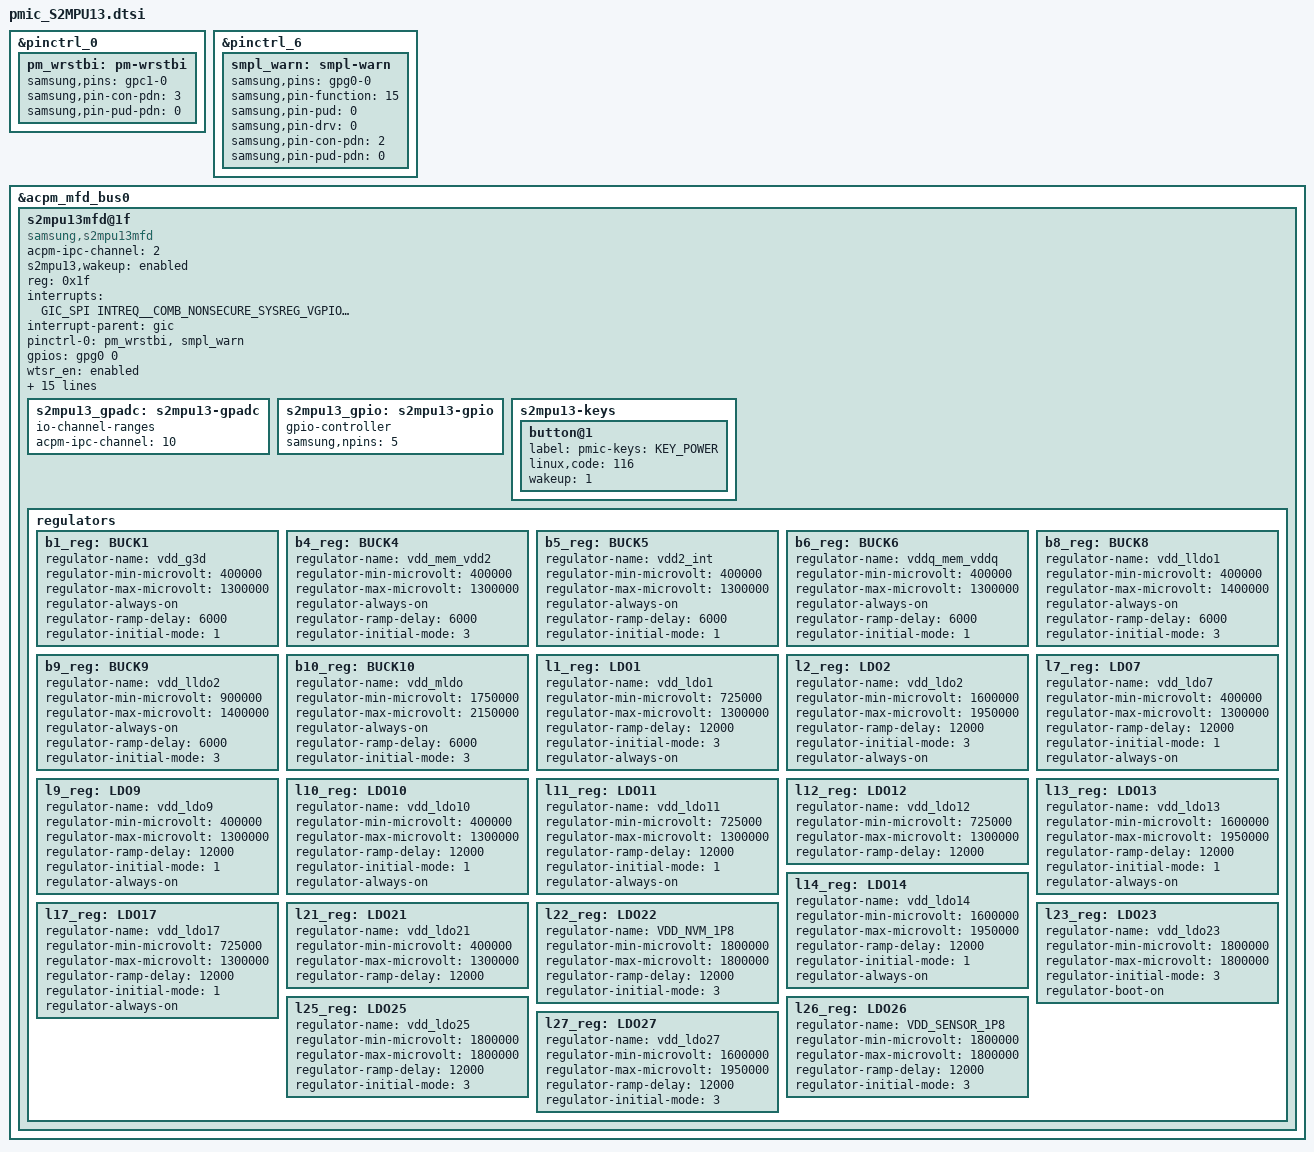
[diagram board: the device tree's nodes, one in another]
#include <dt-bindings/interrupt-controller/s5e8825.h>

&pinctrl_0 {
	pm_wrstbi: pm-wrstbi {
		   samsung,pins = "gpc1-0";
		   samsung,pin-con-pdn = <3>;
		   samsung,pin-pud-pdn = <0>;
	};
};

&pinctrl_6 {
	smpl_warn: smpl-warn {
		   samsung,pins = "gpg0-0";
		   samsung,pin-function = <15>;
		   samsung,pin-pud = <0>;
		   samsung,pin-drv = <0>;
		   samsung,pin-con-pdn = <2>;
		   samsung,pin-pud-pdn = <0>;
	};
};

&acpm_mfd_bus0 {
	status = "okay";
	#address-cells = <1>;
	#size-cells = <0>;

	s2mpu13mfd@1f {
		compatible = "samsung,s2mpu13mfd";
		acpm-ipc-channel = <2>;
		s2mpu13,wakeup = "enabled";
		reg = <0x1f>;
		interrupts = <GIC_SPI INTREQ__COMB_NONSECURE_SYSREG_VGPIO2AP IRQ_TYPE_LEVEL_HIGH>;
		interrupt-parent = <&gic>;
		pinctrl-names = "default";
		pinctrl-0 = <&pm_wrstbi &smpl_warn>;
		gpios = <&gpg0 0 0>;
		/* RTC: wtsr/smpl */
		wtsr_en = "enabled"; /* enable */
		smpl_en = "enabled"; /* enable */
		wtsr_timer_val = <3>;	/* 1000ms */
		smpl_timer_val = <0>;	/* 100ms */
		sub_smpl_en = "enabled"; /* enable */
		check_jigon = <0>; /* do not check jigon */
		/* RTC: If it's first boot, reset rtc to 1/1/2021 12:00:00(Wed) */
		init_time,sec = <0>;
		init_time,min = <0>;
		init_time,hour = <12>;
		init_time,mday = <1>;
		init_time,mon = <0>;
		init_time,year = <121>;
		init_time,wday = <5>;
		/* SMPL_WARN */
		smpl_warn_en = <1>; /* 1 : enable , 0 : disable */

		/* SEL_VGPIO0M~18M (CONTROL_SEL#) */
		sel_vgpio = <0x24 0x32 0x11 0x39 0x33 0x33 0x22 0x33 0x24 0xB1
			     0xC1 0xB1 0x77 0x5B 0x5E 0xCC 0x73 0x33 0xF3>;

		s2mpu13_gpadc: s2mpu13-gpadc {
			#io-channel-cells = <1>;
			io-channel-ranges;
			acpm-ipc-channel = <10>;
		};

		s2mpu13_gpio: s2mpu13-gpio {
			gpio-controller;
			#gpio-cells = <2>;
			samsung,npins = <5>;
			status = "okay";
		};

		s2mpu13-keys {
			button@1 {
				label = "pmic-keys: KEY_POWER";
				linux,code = <116>;
				wakeup = <1>;
			};
		};

		regulators {
			b1_reg: BUCK1 {
				regulator-name = "vdd_g3d";
				regulator-min-microvolt = <400000>;
				regulator-max-microvolt = <1300000>;
				regulator-always-on;
				regulator-ramp-delay = <6000>;
				regulator-initial-mode = <1>;                   /* V_PWREN_G3D */
			};
/*
			b2_reg: BUCK2 {
				regulator-name = "vdd_cpu_cp";
				regulator-min-microvolt = <400000>;
				regulator-max-microvolt = <1300000>;
				regulator-always-on;
				regulator-ramp-delay = <6000>;
				regulator-initial-mode = <3>;
			};

			b3_reg: BUCK3 {
				regulator-name = "vdd_cp";
				regulator-min-microvolt = <400000>;
				regulator-max-microvolt = <1300000>;
				regulator-always-on;
				regulator-ramp-delay = <6000>;
				regulator-initial-mode = <3>;
			};
*/
			b4_reg: BUCK4 {
				regulator-name = "vdd_mem_vdd2";
				regulator-min-microvolt = <400000>;
				regulator-max-microvolt = <1300000>;
				regulator-always-on;
				regulator-ramp-delay = <6000>;
				regulator-initial-mode = <3>;                   /* V_PWREN_MIF */
			};

			b5_reg: BUCK5 {
				regulator-name = "vdd2_int";
				regulator-min-microvolt = <400000>;
				regulator-max-microvolt = <1300000>;
				regulator-always-on;
				regulator-ramp-delay = <6000>;
				regulator-initial-mode = <1>;                   /* V_PWREN_MIF */
			};

			b6_reg: BUCK6 {
				regulator-name = "vddq_mem_vddq";
				regulator-min-microvolt = <400000>;
				regulator-max-microvolt = <1300000>;
				regulator-always-on;
				regulator-ramp-delay = <6000>;
				regulator-initial-mode = <1>;                   /* V_PWREN_MIF */
			};
/*
			b7_reg: BUCK7 {
				regulator-name = "vdd_wlbt";
				regulator-min-microvolt = <400000>;
				regulator-max-microvolt = <1300000>;
				regulator-always-on;
				regulator-ramp-delay = <6000>;
				regulator-initial-mode = <3>;
			};
*/
			b8_reg: BUCK8 {
				regulator-name = "vdd_lldo1";
				regulator-min-microvolt = <400000>;
				regulator-max-microvolt = <1400000>;
				regulator-always-on;
				regulator-ramp-delay = <6000>;
				regulator-initial-mode = <3>;
				};

			b9_reg: BUCK9 {
				regulator-name = "vdd_lldo2";
				regulator-min-microvolt = <900000>;
				regulator-max-microvolt = <1400000>;
				regulator-always-on;
				regulator-ramp-delay = <6000>;
				regulator-initial-mode = <3>;
			};

			b10_reg: BUCK10 {
				regulator-name = "vdd_mldo";
				regulator-min-microvolt = <1750000>;
				regulator-max-microvolt = <2150000>;
				regulator-always-on;
				regulator-ramp-delay = <6000>;
				regulator-initial-mode = <3>;
			};

			l1_reg: LDO1 {
				regulator-name = "vdd_ldo1";
				regulator-min-microvolt = <725000>;
				regulator-max-microvolt = <1300000>;
				regulator-ramp-delay = <12000>;regulator-initial-mode = <3>;
				regulator-always-on;
			};

			l2_reg: LDO2 {
				regulator-name = "vdd_ldo2";
				regulator-min-microvolt = <1600000>;
				regulator-max-microvolt = <1950000>;
				regulator-ramp-delay = <12000>;regulator-initial-mode = <3>;
				regulator-always-on;
			};
/*
			l3_reg: LDO3 {
				regulator-name = "${LDO3_name}";
				regulator-min-microvolt = <${LDO3_Vmin}>;
				regulator-max-microvolt = <${LDO3_Vmax}>;
				${LDO3_opt_properties}
				${LDO3_basic_properties}
			};

			l4_reg: LDO4 {
				regulator-name = "${LDO4_name}";
				regulator-min-microvolt = <${LDO4_Vmin}>;
				regulator-max-microvolt = <${LDO4_Vmax}>;
				${LDO4_opt_properties}
				${LDO4_basic_properties}
			};

			l5_reg: LDO5 {
				regulator-name = "${LDO5_name}";
				regulator-min-microvolt = <${LDO5_Vmin}>;
				regulator-max-microvolt = <${LDO5_Vmax}>;
				${LDO5_opt_properties}
				${LDO5_basic_properties}
			};

			l6_reg: LDO6 {
				regulator-name = "${LDO6_name}";
				regulator-min-microvolt = <${LDO6_Vmin}>;
				regulator-max-microvolt = <${LDO6_Vmax}>;
				${LDO6_opt_properties}
				${LDO6_basic_properties}
			};
*/
			l7_reg: LDO7 {
				regulator-name = "vdd_ldo7";
				regulator-min-microvolt = <400000>;
				regulator-max-microvolt = <1300000>;
				regulator-ramp-delay = <12000>;regulator-initial-mode = <1>;
				regulator-always-on;
			};
/*
			l8_reg: LDO8 {
				regulator-name = "${LDO8_name}";
				regulator-min-microvolt = <${LDO8_Vmin}>;
				regulator-max-microvolt = <${LDO8_Vmax}>;
				${LDO8_opt_properties}
				${LDO8_basic_properties}
			};
*/
			l9_reg: LDO9 {
				regulator-name = "vdd_ldo9";
				regulator-min-microvolt = <400000>;
				regulator-max-microvolt = <1300000>;
				regulator-ramp-delay = <12000>;regulator-initial-mode = <1>;
				regulator-always-on;
			};

			l10_reg: LDO10 {
				regulator-name = "vdd_ldo10";
				regulator-min-microvolt = <400000>;
				regulator-max-microvolt = <1300000>;
				regulator-ramp-delay = <12000>;regulator-initial-mode = <1>;
				regulator-always-on;
			};

			l11_reg: LDO11 {
				regulator-name = "vdd_ldo11";
				regulator-min-microvolt = <725000>;
				regulator-max-microvolt = <1300000>;
				regulator-ramp-delay = <12000>;regulator-initial-mode = <1>;
				regulator-always-on;
			};

			l12_reg: LDO12 {
				regulator-name = "vdd_ldo12";
				regulator-min-microvolt = <725000>;
				regulator-max-microvolt = <1300000>;
				regulator-ramp-delay = <12000>;
				
			};

			l13_reg: LDO13 {
				regulator-name = "vdd_ldo13";
				regulator-min-microvolt = <1600000>;
				regulator-max-microvolt = <1950000>;
				regulator-ramp-delay = <12000>;regulator-initial-mode = <1>;
				regulator-always-on;
			};

			l14_reg: LDO14 {
				regulator-name = "vdd_ldo14";
				regulator-min-microvolt = <1600000>;
				regulator-max-microvolt = <1950000>;
				regulator-ramp-delay = <12000>;regulator-initial-mode = <1>;
				regulator-always-on;
			};
/*
			l15_reg: LDO15 {
				regulator-name = "${LDO15_name}";
				regulator-min-microvolt = <${LDO15_Vmin}>;
				regulator-max-microvolt = <${LDO15_Vmax}>;
				${LDO15_opt_properties}
				${LDO15_basic_properties}
			};

			l16_reg: LDO16 {
				regulator-name = "${LDO16_name}";
				regulator-min-microvolt = <${LDO16_Vmin}>;
				regulator-max-microvolt = <${LDO16_Vmax}>;
				${LDO16_opt_properties}
				${LDO16_basic_properties}
			};
*/
			l17_reg: LDO17 {
				regulator-name = "vdd_ldo17";
				regulator-min-microvolt = <725000>;
				regulator-max-microvolt = <1300000>;
				regulator-ramp-delay = <12000>;regulator-initial-mode = <1>;
				regulator-always-on;
			};
/*
			l18_reg: LDO18 {
				regulator-name = "${LDO18_name}";
				regulator-min-microvolt = <${LDO18_Vmin}>;
				regulator-max-microvolt = <${LDO18_Vmax}>;
				${LDO18_opt_properties}
				${LDO18_basic_properties}
			};

			l19_reg: LDO19 {
				regulator-name = "${LDO19_name}";
				regulator-min-microvolt = <${LDO19_Vmin}>;
				regulator-max-microvolt = <${LDO19_Vmax}>;
				${LDO19_opt_properties}
				${LDO19_basic_properties}
			};

			l20_reg: LDO20 {
				regulator-name = "${LDO20_name}";
				regulator-min-microvolt = <${LDO20_Vmin}>;
				regulator-max-microvolt = <${LDO20_Vmax}>;
				${LDO20_opt_properties}
				${LDO20_basic_properties}
			};
*/
			l21_reg: LDO21 {
				regulator-name = "vdd_ldo21";
				regulator-min-microvolt = <400000>;
				regulator-max-microvolt = <1300000>;
				regulator-ramp-delay = <12000>;
				
			};

			l22_reg: LDO22 {
				regulator-name = "VDD_NVM_1P8";
				regulator-min-microvolt = <1800000>;
				regulator-max-microvolt = <1800000>;
				regulator-ramp-delay = <12000>;regulator-initial-mode = <3>;
				
			};

			l23_reg: LDO23 {
				regulator-name = "vdd_ldo23";
				regulator-min-microvolt = <1800000>;
				regulator-max-microvolt = <1800000>;
				regulator-initial-mode = <3>;
				regulator-boot-on;
			};
/*
			l24_reg: LDO24 {
				regulator-name = "${LDO24_name}";
				regulator-min-microvolt = <${LDO24_Vmin}>;
				regulator-max-microvolt = <${LDO24_Vmax}>;
				${LDO24_opt_properties}
				${LDO24_basic_properties}
			};
*/
			l25_reg: LDO25 {
				regulator-name = "vdd_ldo25";
				regulator-min-microvolt = <1800000>;
				regulator-max-microvolt = <1800000>;
				regulator-ramp-delay = <12000>;regulator-initial-mode = <3>;
				
			};

			l26_reg: LDO26 {
				regulator-name = "VDD_SENSOR_1P8";
				regulator-min-microvolt = <1800000>;
				regulator-max-microvolt = <1800000>;
				regulator-ramp-delay = <12000>;regulator-initial-mode = <3>;
				
			};

			l27_reg: LDO27 {
				regulator-name = "vdd_ldo27";
				regulator-min-microvolt = <1600000>;
				regulator-max-microvolt = <1950000>;
				regulator-ramp-delay = <12000>;regulator-initial-mode = <3>;
				
			};
		}; /* end of regulators */
	}; /* end of s2mpu13mfd@1f */
}; /* end of acpm_mfd_bus0 */
